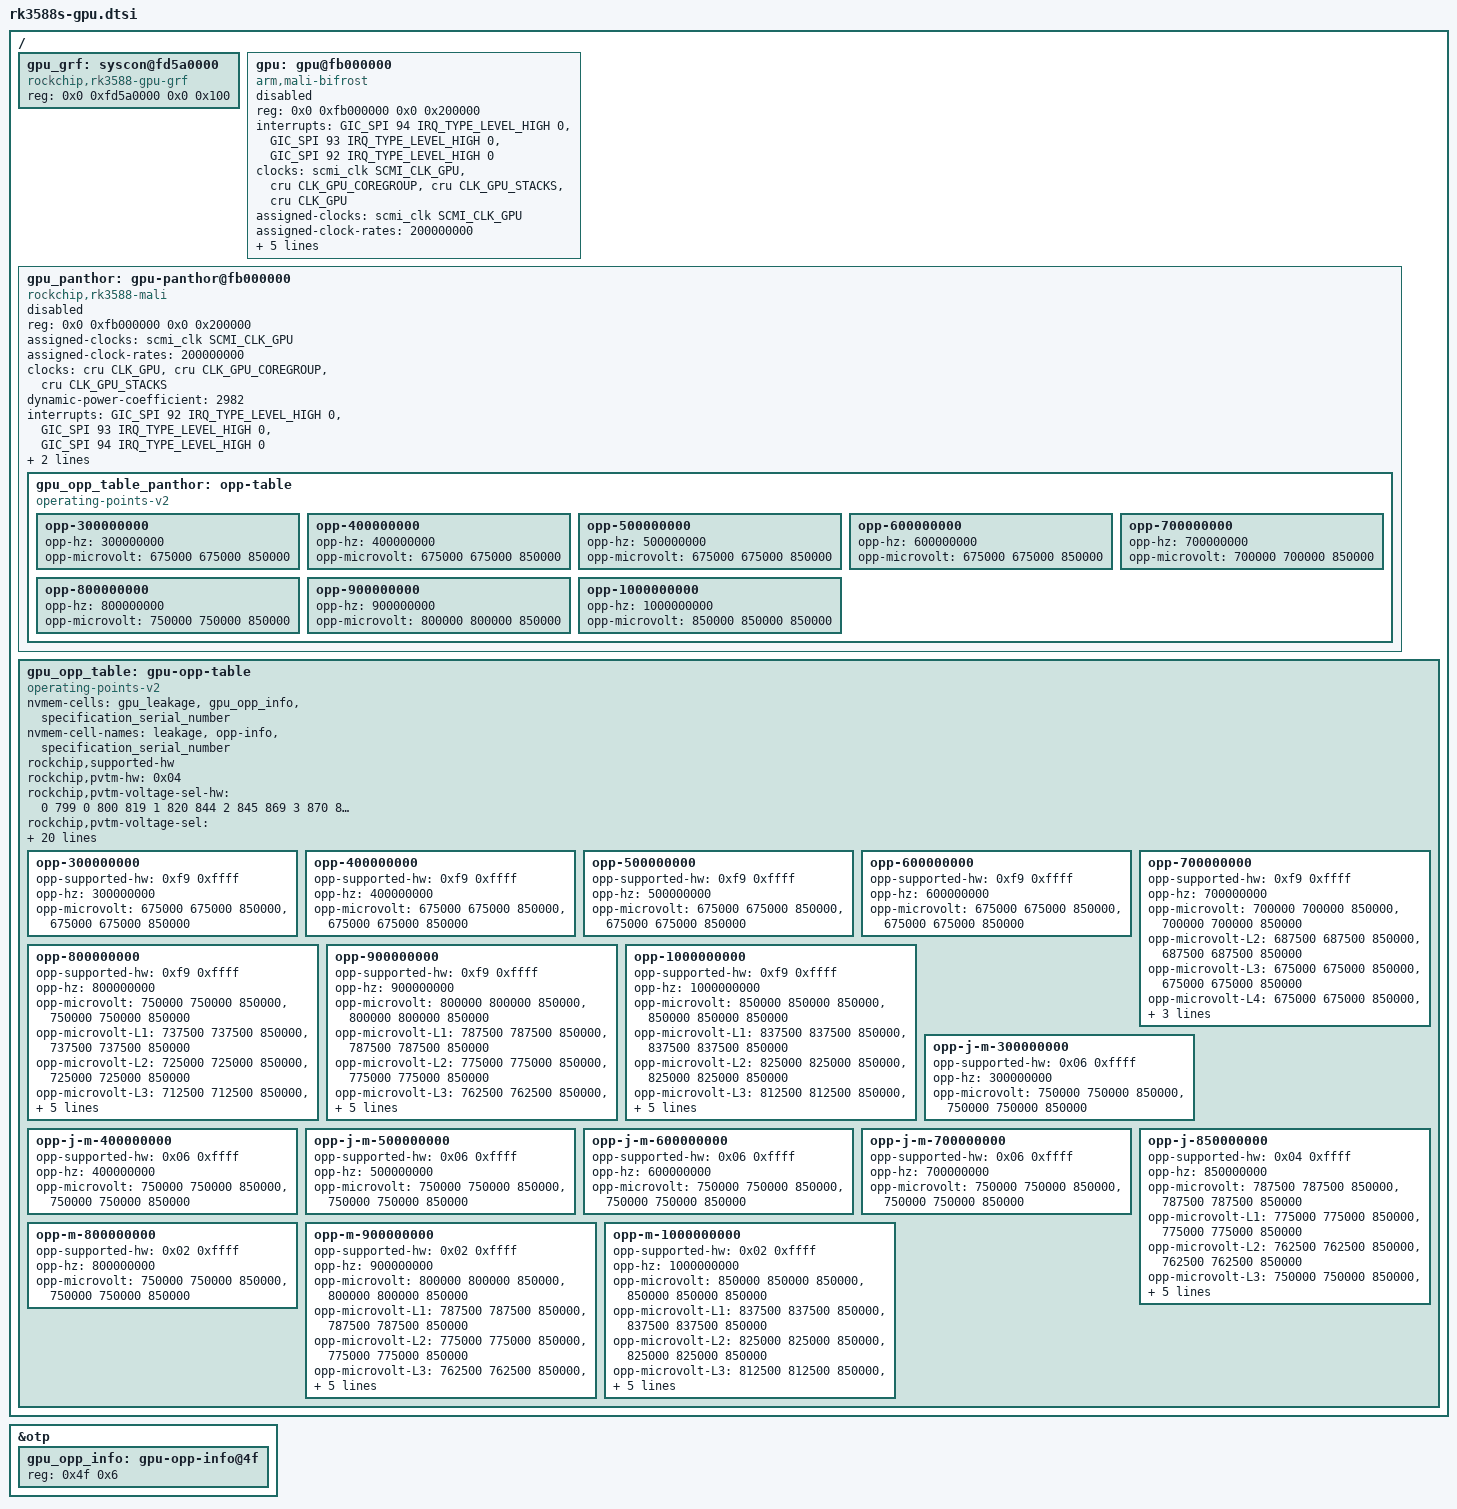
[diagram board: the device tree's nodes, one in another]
/*
 * Copyright (c) 2021 Rockchip Electronics Co., Ltd.
 * Copyright (c) 2025 jjm2473 <jjm2473@gmail.com>
 */

/delete-node/ &gpu;
/delete-node/ &gpu_opp_table;

&otp {
	gpu_opp_info: gpu-opp-info@4f {
		reg = <0x4f 0x6>;
	};
};

/ {
	gpu_grf: syscon@fd5a0000 {
		compatible = "rockchip,rk3588-gpu-grf", "syscon";
		reg = <0x0 0xfd5a0000 0x0 0x100>;
	};

	gpu: gpu@fb000000 {
		compatible = "arm,mali-bifrost";
		reg = <0x0 0xfb000000 0x0 0x200000>;
		interrupts = <GIC_SPI 94 IRQ_TYPE_LEVEL_HIGH 0>,
			     <GIC_SPI 93 IRQ_TYPE_LEVEL_HIGH 0>,
			     <GIC_SPI 92 IRQ_TYPE_LEVEL_HIGH 0>;
		interrupt-names = "GPU", "MMU", "JOB";

		clocks = <&scmi_clk SCMI_CLK_GPU>, <&cru CLK_GPU_COREGROUP>,
			 <&cru CLK_GPU_STACKS>, <&cru CLK_GPU>;
		clock-names = "clk_mali", "clk_gpu_coregroup",
			      "clk_gpu_stacks", "clk_gpu";
		assigned-clocks = <&scmi_clk SCMI_CLK_GPU>;
		assigned-clock-rates = <200000000>;
		power-domains = <&power RK3588_PD_GPU>;
		operating-points-v2 = <&gpu_opp_table>;
		#cooling-cells = <2>;
		dynamic-power-coefficient = <2982>;

		upthreshold = <30>;
		downdifferential = <10>;

		status = "disabled";
	};

	gpu_panthor: gpu-panthor@fb000000 {
		compatible = "rockchip,rk3588-mali", "arm,mali-valhall-csf";
		reg = <0x0 0xfb000000 0x0 0x200000>;
		#cooling-cells = <2>;
		assigned-clocks = <&scmi_clk SCMI_CLK_GPU>;
		assigned-clock-rates = <200000000>;
		clocks = <&cru CLK_GPU>, <&cru CLK_GPU_COREGROUP>,
			 <&cru CLK_GPU_STACKS>;
		clock-names = "core", "coregroup", "stacks";
		dynamic-power-coefficient = <2982>;
		interrupts = <GIC_SPI 92 IRQ_TYPE_LEVEL_HIGH 0>,
			     <GIC_SPI 93 IRQ_TYPE_LEVEL_HIGH 0>,
			     <GIC_SPI 94 IRQ_TYPE_LEVEL_HIGH 0>;
		interrupt-names = "job", "mmu", "gpu";
		operating-points-v2 = <&gpu_opp_table_panthor>;
		power-domains = <&power RK3588_PD_GPU>;
		status = "disabled";

		gpu_opp_table_panthor: opp-table {
			compatible = "operating-points-v2";

			opp-300000000 {
				opp-hz = /bits/ 64 <300000000>;
				opp-microvolt = <675000 675000 850000>;
			};
			opp-400000000 {
				opp-hz = /bits/ 64 <400000000>;
				opp-microvolt = <675000 675000 850000>;
			};
			opp-500000000 {
				opp-hz = /bits/ 64 <500000000>;
				opp-microvolt = <675000 675000 850000>;
			};
			opp-600000000 {
				opp-hz = /bits/ 64 <600000000>;
				opp-microvolt = <675000 675000 850000>;
			};
			opp-700000000 {
				opp-hz = /bits/ 64 <700000000>;
				opp-microvolt = <700000 700000 850000>;
			};
			opp-800000000 {
				opp-hz = /bits/ 64 <800000000>;
				opp-microvolt = <750000 750000 850000>;
			};
			opp-900000000 {
				opp-hz = /bits/ 64 <900000000>;
				opp-microvolt = <800000 800000 850000>;
			};
			opp-1000000000 {
				opp-hz = /bits/ 64 <1000000000>;
				opp-microvolt = <850000 850000 850000>;
			};
		};
	};

	gpu_opp_table: gpu-opp-table {
		compatible = "operating-points-v2";

		nvmem-cells = <&gpu_leakage>, <&gpu_opp_info>, <&specification_serial_number>;
		nvmem-cell-names = "leakage", "opp-info", "specification_serial_number";
		rockchip,supported-hw;

		rockchip,pvtm-hw = <0x04>;
		rockchip,pvtm-voltage-sel-hw = <
			0	799	0
			800	819	1
			820	844	2
			845	869	3
			870	894	4
			895	9999	5
		>;
		rockchip,pvtm-voltage-sel = <
			0	815	0
			816	835	1
			836	860	2
			861	885	3
			886	910	4
			911	9999	5
		>;
		rockchip,pvtm-pvtpll;
		rockchip,pvtm-offset = <0x1c>;
		rockchip,pvtm-sample-time = <1100>;
		rockchip,pvtm-freq = <800000>;
		rockchip,pvtm-volt = <750000>;
		rockchip,pvtm-ref-temp = <25>;
		rockchip,pvtm-temp-prop = <(-135) (-135)>;
		rockchip,pvtm-thermal-zone = "gpu-thermal";

		rockchip,opp-clocks = <&cru CLK_GPU>;
		rockchip,grf = <&gpu_grf>;
		volt-mem-read-margin = <
			855000	1
			765000	2
			675000	3
			495000	4
		>;
		low-volt-mem-read-margin = <4>;
		intermediate-threshold-freq = <400000>;	/* KHz */

		rockchip,temp-hysteresis = <5000>;
		rockchip,low-temp = <15000>;
		rockchip,low-temp-min-volt = <750000>;
		rockchip,high-temp = <85000>;
		rockchip,high-temp-max-freq = <800000>;

		/* RK3588 gpu OPPs */
		opp-300000000 {
			opp-supported-hw = <0xf9 0xffff>;
			opp-hz = /bits/ 64 <300000000>;
			opp-microvolt = <675000 675000 850000>,
					<675000 675000 850000>;
		};
		opp-400000000 {
			opp-supported-hw = <0xf9 0xffff>;
			opp-hz = /bits/ 64 <400000000>;
			opp-microvolt = <675000 675000 850000>,
					<675000 675000 850000>;
		};
		opp-500000000 {
			opp-supported-hw = <0xf9 0xffff>;
			opp-hz = /bits/ 64 <500000000>;
			opp-microvolt = <675000 675000 850000>,
					<675000 675000 850000>;
		};
		opp-600000000 {
			opp-supported-hw = <0xf9 0xffff>;
			opp-hz = /bits/ 64 <600000000>;
			opp-microvolt = <675000 675000 850000>,
					<675000 675000 850000>;
		};
		opp-700000000 {
			opp-supported-hw = <0xf9 0xffff>;
			opp-hz = /bits/ 64 <700000000>;
			opp-microvolt = <700000 700000 850000>,
					<700000 700000 850000>;
			opp-microvolt-L2 = <687500 687500 850000>,
					   <687500 687500 850000>;
			opp-microvolt-L3 = <675000 675000 850000>,
					   <675000 675000 850000>;
			opp-microvolt-L4 = <675000 675000 850000>,
					   <675000 675000 850000>;
			opp-microvolt-L5 = <675000 675000 850000>,
					   <675000 675000 850000>;
		};
		opp-800000000 {
			opp-supported-hw = <0xf9 0xffff>;
			opp-hz = /bits/ 64 <800000000>;
			opp-microvolt = <750000 750000 850000>,
					<750000 750000 850000>;
			opp-microvolt-L1 = <737500 737500 850000>,
					   <737500 737500 850000>;
			opp-microvolt-L2 = <725000 725000 850000>,
					   <725000 725000 850000>;
			opp-microvolt-L3 = <712500 712500 850000>,
					   <712500 712500 850000>;
			opp-microvolt-L4 = <700000 700000 850000>,
					   <700000 700000 850000>;
			opp-microvolt-L5 = <700000 700000 850000>,
					   <700000 700000 850000>;
		};
		opp-900000000 {
			opp-supported-hw = <0xf9 0xffff>;
			opp-hz = /bits/ 64 <900000000>;
			opp-microvolt = <800000 800000 850000>,
					<800000 800000 850000>;
			opp-microvolt-L1 = <787500 787500 850000>,
					   <787500 787500 850000>;
			opp-microvolt-L2 = <775000 775000 850000>,
					   <775000 775000 850000>;
			opp-microvolt-L3 = <762500 762500 850000>,
					   <762500 762500 850000>;
			opp-microvolt-L4 = <750000 750000 850000>,
					   <750000 750000 850000>;
			opp-microvolt-L5 = <737500 737500 850000>,
					   <737500 737500 850000>;
		};
		opp-1000000000 {
			opp-supported-hw = <0xf9 0xffff>;
			opp-hz = /bits/ 64 <1000000000>;
			opp-microvolt = <850000 850000 850000>,
					<850000 850000 850000>;
			opp-microvolt-L1 = <837500 837500 850000>,
					   <837500 837500 850000>;
			opp-microvolt-L2 = <825000 825000 850000>,
					   <825000 825000 850000>;
			opp-microvolt-L3 = <812500 812500 850000>,
					   <812500 812500 850000>;
			opp-microvolt-L4 = <800000 800000 850000>,
					   <800000 800000 850000>;
			opp-microvolt-L5 = <787500 787500 850000>,
					   <787500 787500 850000>;
		};

		/* RK3588J/M gpu OPPs */
		opp-j-m-300000000 {
			opp-supported-hw = <0x06 0xffff>;
			opp-hz = /bits/ 64 <300000000>;
			opp-microvolt = <750000 750000 850000>,
					<750000 750000 850000>;
		};
		opp-j-m-400000000 {
			opp-supported-hw = <0x06 0xffff>;
			opp-hz = /bits/ 64 <400000000>;
			opp-microvolt = <750000 750000 850000>,
					<750000 750000 850000>;
		};
		opp-j-m-500000000 {
			opp-supported-hw = <0x06 0xffff>;
			opp-hz = /bits/ 64 <500000000>;
			opp-microvolt = <750000 750000 850000>,
					<750000 750000 850000>;
		};
		opp-j-m-600000000 {
			opp-supported-hw = <0x06 0xffff>;
			opp-hz = /bits/ 64 <600000000>;
			opp-microvolt = <750000 750000 850000>,
					<750000 750000 850000>;
		};
		opp-j-m-700000000 {
			opp-supported-hw = <0x06 0xffff>;
			opp-hz = /bits/ 64 <700000000>;
			opp-microvolt = <750000 750000 850000>,
					<750000 750000 850000>;
		};
		/* RK3588J gpu OPPs */
		opp-j-850000000 {
			opp-supported-hw = <0x04 0xffff>;
			opp-hz = /bits/ 64 <850000000>;
			opp-microvolt = <787500 787500 850000>,
					<787500 787500 850000>;
			opp-microvolt-L1 = <775000 775000 850000>,
					   <775000 775000 850000>;
			opp-microvolt-L2 = <762500 762500 850000>,
					   <762500 762500 850000>;
			opp-microvolt-L3 = <750000 750000 850000>,
					   <750000 750000 850000>;
			opp-microvolt-L4 = <750000 750000 850000>,
					   <750000 750000 850000>;
			opp-microvolt-L5 = <750000 750000 850000>,
					   <750000 750000 850000>;
		};
		/* RK3588M gpu OPPs */
		opp-m-800000000 {
			opp-supported-hw = <0x02 0xffff>;
			opp-hz = /bits/ 64 <800000000>;
			opp-microvolt = <750000 750000 850000>,
					<750000 750000 850000>;
		};
		opp-m-900000000 {
			opp-supported-hw = <0x02 0xffff>;
			opp-hz = /bits/ 64 <900000000>;
			opp-microvolt = <800000 800000 850000>,
					<800000 800000 850000>;
			opp-microvolt-L1 = <787500 787500 850000>,
					   <787500 787500 850000>;
			opp-microvolt-L2 = <775000 775000 850000>,
					   <775000 775000 850000>;
			opp-microvolt-L3 = <762500 762500 850000>,
					   <762500 762500 850000>;
			opp-microvolt-L4 = <750000 750000 850000>,
					   <750000 750000 850000>;
			opp-microvolt-L5 = <750000 750000 850000>,
					   <750000 750000 850000>;
		};
		opp-m-1000000000 {
			opp-supported-hw = <0x02 0xffff>;
			opp-hz = /bits/ 64 <1000000000>;
			opp-microvolt = <850000 850000 850000>,
					<850000 850000 850000>;
			opp-microvolt-L1 = <837500 837500 850000>,
					   <837500 837500 850000>;
			opp-microvolt-L2 = <825000 825000 850000>,
					   <825000 825000 850000>;
			opp-microvolt-L3 = <812500 812500 850000>,
					   <812500 812500 850000>;
			opp-microvolt-L4 = <800000 800000 850000>,
					   <800000 800000 850000>;
			opp-microvolt-L5 = <787500 787500 850000>,
					   <787500 787500 850000>;
		};
	};

};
